# IWRL6432 register map
File version: 1.0
CPU: CM4 1.0, other endian, MPU, FPU, 3 interrupt priority bits
Registers are 32-bit, read-write, reset 0x0 unless marked. A register's access mark holds for its fields unless they carry their own. Offsets are from the block's base; [hi:lo] are bit positions; {n}, {i} and the like mark numbered series; 'fields as' and 'values as' point back to an identical list.

## APP_RCM
Base 0x56040000
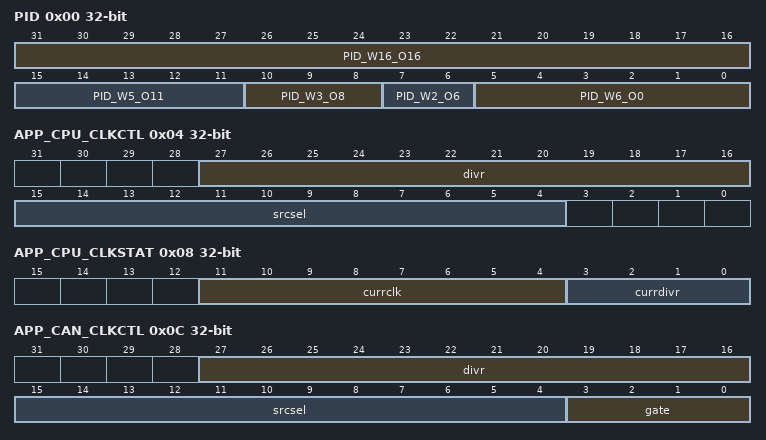
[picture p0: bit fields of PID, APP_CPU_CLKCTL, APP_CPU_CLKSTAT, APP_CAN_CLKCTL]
0x00 PID
  [31:16] PID_W16_O16, [15:11] PID_W5_O11, [10:8] PID_W3_O8, [7:6] PID_W2_O6, [5:0] PID_W6_O0
0x04 APP_CPU_CLKCTL
  [27:16] divr — [27:16] Divide value 0x0 : div1 0x1 : div2 0x2 : div3 . . 0xF = div16 Data should be loaded as multibit. For example: if divider value of '0x8' should be selected then '0x888' should be configured to the register.
  [15:4] srcsel — [15:4] Select the source clock: 0x0 : OSC_CLK 0x1 : SLOW_CLK 0x2 : MDLL_CLK 0x3 : FAST_CLK 0x4 : SLOW_CLK 0x5 : SLOW_CLK 0x6 : SLOW_CLK 0x7 : SLOW_CLK For other values if the lower 3 bits matches with above, corresponding clock is selected. Data should be loaded as multibit. For example: if Clock source 0x5 should be selected then 0x555 should be configured to the register.
0x08 APP_CPU_CLKSTAT
  [11:4] currclk — [11:4] Current Clock selected by GCM Clock Mux 0x1 : XTALCLK 0x2 : XTALCLKX2 0x4 : MDLL 0x8 : APLL/DPLL 0x10 : RCCLK
  [3:0] currdivr — [3:0] Gives the current divr setting used by the clock divider.
0x0C APP_CAN_CLKCTL
  [27:16] divr — [27:16] Divide value 0x0 : div1 0x1 : div2 0x2 : div3 . . 0xF = div16 Data should be loaded as multibit. For example: if divider value of '0x8' should be selected then '0x888' should be configured to the register.
  [15:4] srcsel — [15:4] 0x0 : OSC_CLK 0x1 : OSC_CLKX2 0x2 : MDLL_CLK 0x3 : FAST_CLK 0x4 : SLOW_CLK 0x5 : SLOW_CLK 0x6 : SLOW_CLK 0x7 : SLOW_CLKFor other values if the lower 3 bits matches with above, corresponding clock is selected. Data should be loaded as multibit. For example: if Clock source 0x5 should be selected then 0x555 should be configured to the register.
  [3:0] gate — [3:0] 0x0 : Enable the Clock 0x7 : Gate the clock
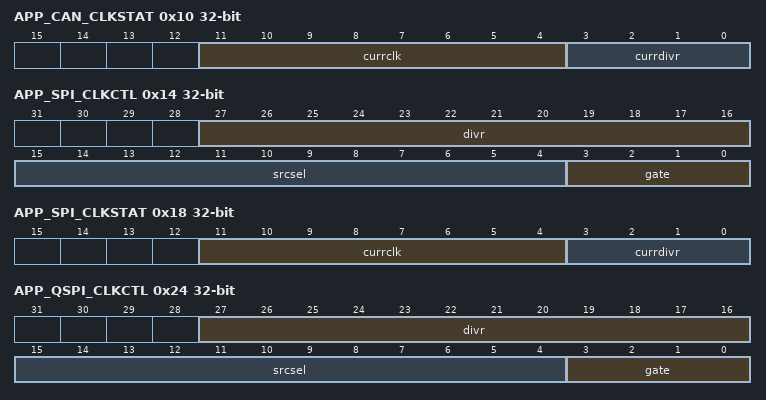
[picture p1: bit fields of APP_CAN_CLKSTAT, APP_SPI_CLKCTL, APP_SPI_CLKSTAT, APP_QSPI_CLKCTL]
0x10 APP_CAN_CLKSTAT
  fields as APP_CPU_CLKSTAT
0x14 APP_SPI_CLKCTL
  [27:16] divr — [27:16] Divide value 0x0 : div1 0x1 : div2 0x2 : div3 . . 0xF = div16 Data should be loaded as multibit. For example: if divider value of '0x8' should be selected then '0x888' should be configured to the register.
  [15:4] srcsel — [15:4] 0x0 : OSC_CLK 0x1 : OSC_CLKX2 0x2 : MDLL_CLK 0x3 : FAST_CLK 0x4 : SLOW_CLK 0x5 : SLOW_CLK 0x6 : SLOW_CLK 0x7 : SLOW_CLK For other values if the lower 3 bits matches with above, corresponding clock is selected. Data should be loaded as multibit. For example: if Clock source 0x5 should be selected then 0x555 should be configured to the register.
  [3:0] gate — [3:0] 0x0 : Enable the Clock 0x7 : Gate the clock
0x18 APP_SPI_CLKSTAT
  fields as APP_CPU_CLKSTAT
0x1C APP_SPI_BUSIF_CLKCTL
  [11:0] divr — [11:0] Divide value 0x0 : div1 0x1 : div2 0x2 : div3 . . 0xF = div16 Data should be loaded as multibit. For example: if divider value of '0x8' should be selected then '0x888' should be configured to the register.
0x20 APP_SPI_BUSIF_CLKSTAT
  [3:0] currdivr — [3:0] Gives the current divr setting used by the clock divider.
0x24 APP_QSPI_CLKCTL
  fields as APP_SPI_CLKCTL
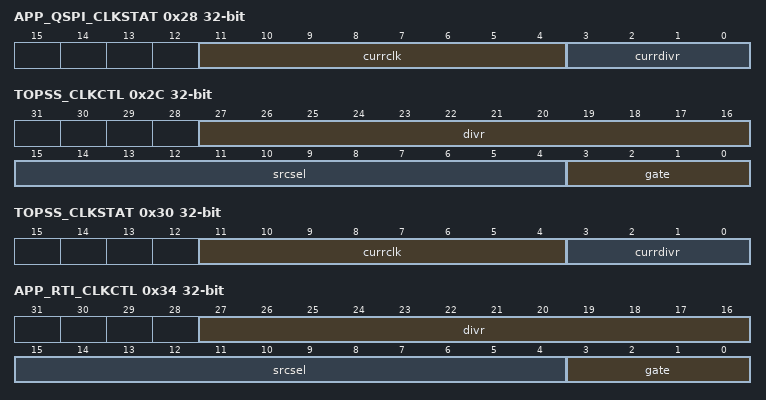
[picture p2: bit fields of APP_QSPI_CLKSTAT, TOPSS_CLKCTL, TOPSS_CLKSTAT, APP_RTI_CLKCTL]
0x28 APP_QSPI_CLKSTAT
  fields as APP_CPU_CLKSTAT
0x2C TOPSS_CLKCTL
  [27:16] divr — [27:16] Divide value 0x0 : div1 0x1 : div2 0x2 : div3 . . 0xF = div16 Data should be loaded as multibit. For example: if divider value of '0x8' should be selected then '0x888' should be configured to the register.
  [15:4] srcsel — [15:4] 0x0 : OSC_CLK 0x1 : SLOW_CLK 0x2 : MDLL 0x3 : FAST_CLK 0x4 : SLOW_CLK For other values if the lower 3 bits matches with above, corresponding clock is selected. Data should be loaded as multibit. For example: if Clock source 0x5 should be selected then 0x555 should be configured to the register.
  [3:0] gate — [3:0] 0x0 : Enable the Clock 0x7 : Gate the clock
0x30 TOPSS_CLKSTAT
  fields as APP_CPU_CLKSTAT
0x34 APP_RTI_CLKCTL
  [27:16] divr — [27:16] Divide value 0x0 : div1 0x1 : div2 0x2 : div3 . . 0xF = div16 Data should be loaded as multibit. For example: if divider value of '0x8' should be selected then '0x888' should be configured to the register.
  [15:4] srcsel — [15:4] 0x0 : OSC_CLK 0x1 : XREF_IN 0x2 : OSC_CLK (Ungated OSC_CLK for RTI in Sleep mode) 0x3 : SLOW_CLK 0x4 : SLOW_CLK 0x5 : SLOW_CLK 0x6 : SLOW_CLK 0x7 : SLOW_CLK For other values if the lower 3 bits matches with above, corresponding clock is selected. Data should be loaded as multibit. For example: if Clock source 0x5 should be selected then 0x555 should be configured to the register.
  [3:0] gate — [3:0] 0x0 : Enable the Clock 0x7 : Gate the clock
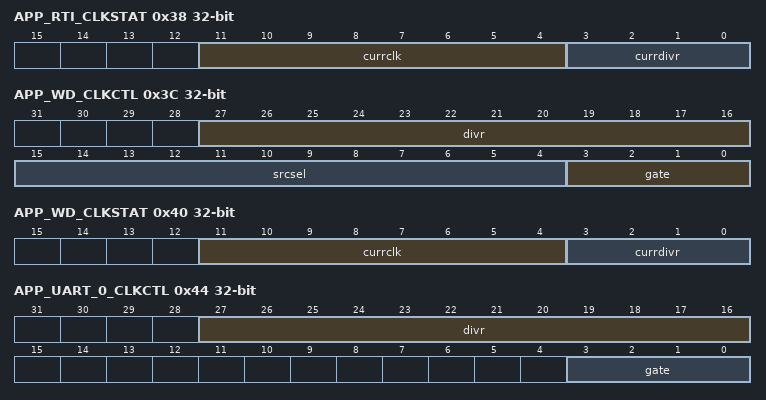
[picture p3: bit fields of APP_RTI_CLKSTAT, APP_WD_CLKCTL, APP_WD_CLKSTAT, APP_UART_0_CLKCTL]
0x38 APP_RTI_CLKSTAT
  fields as APP_CPU_CLKSTAT
0x3C APP_WD_CLKCTL
  [27:16] divr — [27:16] Divide value 0x0 : div1 0x1 : div2 0x2 : div3 . . 0xF = div16 Data should be loaded as multibit. For example: if divider value of '0x8' should be selected then '0x888' should be configured to the register.
  [15:4] srcsel — [15:4] 0x0 : OSC_CLK 0x1 : XREF_IN 0x2 : OSC_CLK 0x3 : SLOW_CLK 0x4 : SLOW_CLK 0x5 : SLOW_CLK 0x6 : SLOW_CLK 0x7 : SLOW_CLK For other values if the lower 3 bits matches with above, corresponding clock is selected. Data should be loaded as multibit. For example: if Clock source 0x5 should be selected then 0x555 should be configured to the register.
  [3:0] gate — [3:0] 0x0 : Enable the Clock 0x7 : Gate the clock
0x40 APP_WD_CLKSTAT
  fields as APP_CPU_CLKSTAT
0x44 APP_UART_0_CLKCTL
  [27:16] divr — [27:16] Divide value 0x0 : div1 0x1 : div2 0x2 : div3 . . 0xF = div16 Data should be loaded as multibit. For example: if divider value of '0x8' should be selected then '0x888' should be configured to the register.
  [3:0] gate — [3:0] 0x0 : Enable the Clock 0x7 : Gate the clock
0x48 APP_UART_0_CLKSTAT
  fields as APP_SPI_BUSIF_CLKSTAT
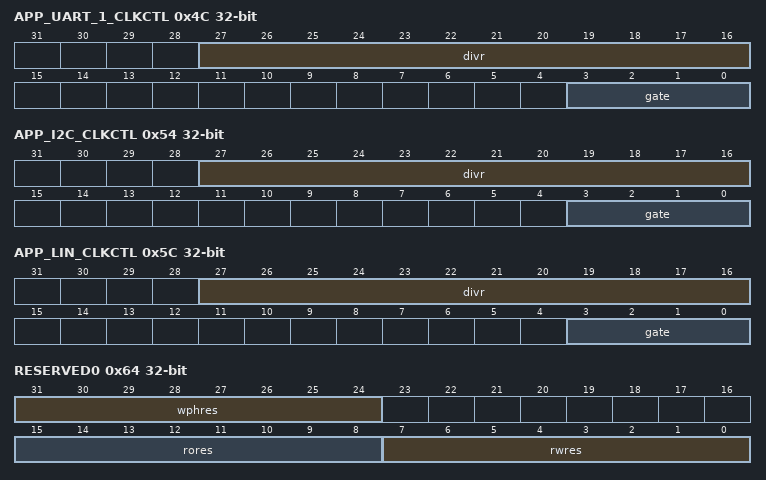
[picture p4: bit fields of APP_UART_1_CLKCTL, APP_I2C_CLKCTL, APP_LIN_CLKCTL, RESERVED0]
0x4C APP_UART_1_CLKCTL
  fields as APP_UART_0_CLKCTL
0x50 APP_UART_1_CLKSTAT
  fields as APP_SPI_BUSIF_CLKSTAT
0x54 APP_I2C_CLKCTL
  fields as APP_UART_0_CLKCTL
0x58 APP_I2C_CLKSTAT
  fields as APP_SPI_BUSIF_CLKSTAT
0x5C APP_LIN_CLKCTL
  fields as APP_UART_0_CLKCTL
0x60 APP_LIN_CLKSTAT
  fields as APP_SPI_BUSIF_CLKSTAT
0x64 RESERVED0
  [31:24] wphres — [31:24] Reserved
  [15:8] rores — [15:8] Reserved
  [7:0] rwres — [7:0] Bit 2:0 - Software reset for hwass cba3to2 and m64top32 bridge instances in appss. (reset value - 0) Bit 5:3 - Software reset for fecss p2p async bridge instance in appss. (reset value - 0) 0x0 : Release the reset 0x7 : Assert the reset Bit 31:6 - Reserved
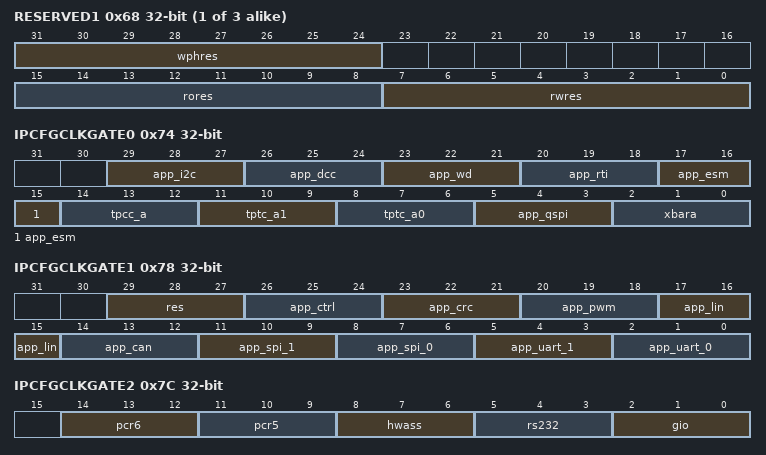
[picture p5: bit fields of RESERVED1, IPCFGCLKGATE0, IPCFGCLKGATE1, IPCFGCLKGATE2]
{0x64+4i} RESERVED{i} (i=1..3)
  [31:24] wphres — [31:24] Reserved
  [15:8] rores — [15:8] Reserved
  [7:0] rwres — [7:0] Reserved
0x74 IPCFGCLKGATE0
  [29:27] app_i2c — [29:27] 0x0 : Enable the Clock 0x7 : Gate the clock
  [26:24] app_dcc — [26:24] 0x0 : Enable the Clock 0x7 : Gate the clock
  [23:21] app_wd — [23:21] 0x0 : Enable the Clock 0x7 : Gate the clock
  [20:18] app_rti — [20:18] 0x0 : Enable the Clock 0x7 : Gate the clock
  [17:15] app_esm — [17:15] 0x0 : Enable the Clock 0x7 : Gate the clock
  [14:12] tpcc_a — [14:12] 0x0 : Enable the Clock 0x7 : Gate the clock
  [11:9] tptc_a1 — [11:9] 0x0 : Enable the Clock 0x7 : Gate the clock
  [8:6] tptc_a0 — [8:6] 0x0 : Enable the Clock 0x7 : Gate the clock
  [5:3] app_qspi — [5:3] 0x0 : Enable the Clock 0x7 : Gate the clock
  [2:0] xbara — [2:0] Reserved Setting this bit does not cause any affect to any logic
0x78 IPCFGCLKGATE1
  [29:27] res — [29:27] 0x0 : Enable the Clock 0x7 : Gate the clock
  [26:24] app_ctrl — [26:24] 0x0 : Enable the Clock 0x7 : Gate the clock
  [23:21] app_crc — [23:21] 0x0 : Enable the Clock 0x7 : Gate the clock
  [20:18] app_pwm — [20:18] 0x0 : Enable the Clock 0x7 : Gate the clock
  [17:15] app_lin — [17:15] 0x0 : Enable the Clock 0x7 : Gate the clock
  [14:12] app_can — [14:12] 0x0 : Enable the Clock 0x7 : Gate the clock
  [11:9] app_spi_1 — [11:9] 0x0 : Enable the Clock 0x7 : Gate the clock
  [8:6] app_spi_0 — [8:6] 0x0 : Enable the Clock 0x7 : Gate the clock
  [5:3] app_uart_1 — [5:3] 0x0 : Enable the Clock 0x7 : Gate the clock
  [2:0] app_uart_0 — [2:0] 0x0 : Enable the Clock 0x7 : Gate the clock
0x7C IPCFGCLKGATE2
  [14:12] pcr6 — [14:12] 0x0 : Enable the Clock 0x7 : Gate the clock
  [11:9] pcr5 — [11:9] 0x0 : Enable the Clock 0x7 : Gate the clock
  [8:6] hwass — [8:6] 0x0 : Enable the Clock 0x7 : Gate the clock
  [5:3] rs232 — [5:3] 0x0 : Enable the Clock 0x7 : Gate the clock
  [2:0] gio — [2:0] 0x0 : Enable the Clock 0x7 : Gate the clock
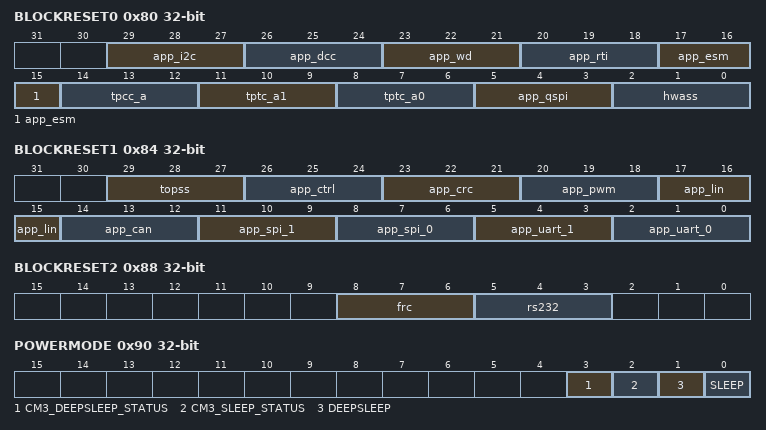
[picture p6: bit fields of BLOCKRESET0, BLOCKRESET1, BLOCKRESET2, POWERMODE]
0x80 BLOCKRESET0
  [29:27] app_i2c — [29:27] 0x0 : Release the reset 0x7 : Assert the reset
  [26:24] app_dcc — [26:24] 0x0 : Release the reset 0x7 : Assert the reset
  [23:21] app_wd — [23:21] 0x0 : Release the reset 0x7 : Assert the reset
  [20:18] app_rti — [20:18] 0x0 : Release the reset 0x7 : Assert the reset
  [17:15] app_esm — [17:15] 0x0 : Release the reset 0x7 : Assert the reset
  [14:12] tpcc_a — [14:12] 0x0 : Release the reset 0x7 : Assert the reset
  [11:9] tptc_a1 — [11:9] 0x0 : Release the reset 0x7 : Assert the reset
  [8:6] tptc_a0 — [8:6] 0x0 : Release the reset 0x7 : Assert the reset
  [5:3] app_qspi — [5:3] 0x0 : Release the reset 0x7 : Assert the reset
  [2:0] hwass — [2:0] 0x0 : Release the reset 0x7 : Assert the reset
0x84 BLOCKRESET1
  [29:27] topss — [29:27] 0x0 : Release the reset 0x7 : Assert the reset
  [26:24] app_ctrl — [26:24] 0x0 : Release the reset 0x7 : Assert the reset
  [23:21] app_crc — [23:21] 0x0 : Release the reset 0x7 : Assert the reset
  [20:18] app_pwm — [20:18] 0x0 : Release the reset 0x7 : Assert the reset
  [17:15] app_lin — [17:15] 0x0 : Release the reset 0x7 : Assert the reset
  [14:12] app_can — [14:12] 0x0 : Release the reset 0x7 : Assert the reset
  [11:9] app_spi_1 — [11:9] 0x0 : Release the reset 0x7 : Assert the reset
  [8:6] app_spi_0 — [8:6] 0x0 : Release the reset 0x7 : Assert the reset
  [5:3] app_uart_1 — [5:3] 0x0 : Release the reset 0x7 : Assert the reset
  [2:0] app_uart_0 — [2:0] 0x0 : Release the reset 0x7 : Assert the reset
0x88 BLOCKRESET2
  [8:6] frc — [8:6] 0x0 : Release the reset 0x7 : Assert the reset
  [5:3] rs232 — [5:3] 0x0 : Release the reset 0x7 : Assert the reset
0x8C PLATFORM_SIGNATURE
  [31:0] signature — [31:0] Platform signature to identify the platform
0x90 POWERMODE
  [3] CM3_DEEPSLEEP_STATUS — [3:3] CM3 Core Deep Sleep Status
  [2] CM3_SLEEP_STATUS — [2:2] CM3 Core Sleep Status
  [1] DEEPSLEEP — [1:1] 0x0 : CM4 CORE DEEP SLEEP 0x1 : DEVICE DEEP SLEEP
  [0] SLEEP — [0:0] 0x0 : CM4 CORE SLEEP 0x1 : DEVICE SLEEP
0x94 RST_WFICHECK
  [2:0] cpu — [2:0] Writing '000' will disable check for WFI before local reset assertion of app cpu
0x98 RST_ASSERTDLY
  [7:0] common — [7:0] Value decides number of cycles reset should be asserted for cpu
0x9C RST2ASSERTDLY
  [15:8] cpu — [15:8] Value decides number of cycles to be held before asserting reset for app cpu
0xA0 RST_FSM_TRIG
  [2:0] cpu — [2:0] FSM Reset Trigger
0xA4 RST_CAUSE
  [7:0] common — [7:0] Reset cause register for APP CPU 0x00 - All cleared 0x01 - Power On Reset (PoR) 0x02 - Subsystem Reset (Combination of Warm Reset initiated from PRCM using LPRADAR:TOP_PRCM:RST_APP_PD_SOFT_RESET and PoR reset) 0x04 - STC RESET 0x08 - Reserved 0x10 - CPU Only Reset triggered by writing to LPRADAR:APP_RCM:RST_FSM_TRIG<RST_FSM_TRIG_CPU> (self triggered CPU reset during MEMSWAP/ECLIPSE mode to wait for WFI to assert the reset to CPU) 0x20 - Core Reset initiated from PRCM using LPRADAR:TOP_PRCM:RST_SOFT_APP_CORE_SYSRESET_REQ (reset CPU unconditionally - by debugger) or LPRADAR:TOP_PRCM:APP_CORE_SYSRESET_PARAM_WAKEUP_OUT_STATE 0x40 - Reserved
0xA8 RST_CAUSE_CLR
  [2:0] cpu — [2:0] Writing '111' will clear the RST_CAUSE register
0xAC XTALCLK_CLK_GATE
  [2:0] XTALCLK_CLK_GATE — [2:0] RESERVED
0xB0 XTALCLKX2_CLK_GATE
  [2:0] XTALCLKX2_CLK_GATE — [2:0] Writing 3'b111 will gate the XTALX2 clock.Writing 3'b000 will ungate the clock.
0xB4 APLLDIV2_CLK_GATE
  [2:0] APLLDIV2_CLK_GATE — [2:0] Writing 3'b111 will gate the APLL/2clock to EDCC.Writing 3'b000 will ungate the clock.
0xB8 DFT_APPSS_LSTC_CLK_GATE
  [2:0] DFT_APPSS_LSTC_CLK_GATE — [2:0] Writing 3'b111 will gate the clock to LSTC.Writing 3'b000 will ungate the clock.
0xBC DFT_APPSS_LSTC_VBUSP_CLK_GATE
  [2:0] enable — [2:0] 3'b000 : Gate clock to LSTC VBUSP 3'b111 : Ungate Clock to LSTC VBUSP
0xC0 APP_ROM_CLOCK_GATE
  [2:0] enable — [2:0] 3'b000 : Ungate clock to APP ROM 3'b111 : Gate Clock to APP ROM
0xC4 APP_RAM1_CLOCK_GATE
  [2:0] enable — [2:0] 3'b000 : Ungate clock to APP RAM1 3'b111 : Gate Clock to APP_RAM1
0xC8 APP_RAM2_CLOCK_GATE
  [2:0] enable — [2:0] 3'b000 : Ungate clock to APP RAM2 3'b111 : Gate Clock to APP RAM2
0xCC APP_RAM3_CLOCK_GATE
  [2:0] enable — [2:0] 3'b000 : Ungate clock to APP RAM3 3'b111 : Gate Clock to APP RAM3
0xD0 CFG_XBARA_DYNAMIC_CG
  [2:0] enable — [2:0] Enable APPSS crossbar dynamic clock gating. 1 - Dynamic clock gating feature is enabled. When the feature is enabed, the CM4 should monitor for any possible pending transactions from various masters like DMA/NWA and if no transaction is expected to be iniated by the masters, the CM4 executes WFI. On ssertion of WFI signal, the clock to crossbar is gated. The clock is automatically ungated under two conditions (i) when the WFI signal is deasserted by any interrupted (ii) when any of the APPSS TPCC triggers are asserted. Instead of WFI, cfg_xbara_set_dynamic_cg also can be used to start the clock gating. 0 - Dynamic clock gating feature is disabled. The clock to APPSS crossbar is not gated dynamically. The clock to APPSS crossbar is gated/ungated as per device ice level power states.
0xD4 CFG_TPTC1_DYNAMIC_CG
  [2:0] enable — [2:0] Enable APPSS TPTC1 crossbar dynamic clock gating. 1 - Dynamic clock gating feature is enabled. Same behaviour as cfg_xbara_dynamic_cg_en - for both entry to clock gating and exit from clock gating. WFI or cfg_tptc1_set_dynamic_cg 0 - Dynamic clock gating feature is disabled. The clock to APPSS TPTC1 crossbar is not gated dynamically. The clock to APPSS TPTC1 crossbar is gated/ungated as per device ice level power states.
0xD8 CFG_TPTC2_DYNAMIC_CG
  [2:0] enable — [2:0] Enable APPSS TPTC2 crossbar dynamic clock gating. 1 - Dynamic clock gating feature is enabled. Same behaviour as cfg_xbara_dynamic_cg_en - for both entry to clock gating and exit from clock gating. WFI or cfg_tptc2_set_dynamic_cg 0 - Dynamic clock gating feature is disabled. The clock to APPSS TPTC2 crossbar is not gated dynamically. The clock to APPSS TPTC2 crossbar is gated/ungated as per device ice level power states
0xDC CFG_XBARA_SET_DYNAMIC_CG
  [0] set — [0:0] Start APPSS crossbar dynamic clock gating. This is used instead of WFI. 1 - Start the clock gating. In order to start again, write 0 followed by 1. Rise edge is detected internally, to start the clock gating. 0 - Clock is ungated. Fall edge is detected internally to ungate the clock.
0xE0 CFG_TPTC1_SET_DYNAMIC_CG
  [0] set — [0:0] Start APPSS tptc1 dynamic clock gating. This is used instead of WFI. 1 - Start the clock gating. In order to start again, write 0 followed by 1. Rise edge is detected internally, to start the clock gating. 0 - Clock is ungated. Fall edge is detected internally to ungate the clock.
0xE4 CFG_TPTC2_SET_DYNAMIC_CG
  [0] set — [0:0] Start APPSS tptc2 dynamic clock gating. This is used instead of WFI. 1 - Start the clock gating. In order to start again, write 0 followed by 1. Rise edge is detected internally, to start the clock gating. 0 - Clock is ungated. Fall edge is detected internally to ungate the clock.
0xE8 CM4_FORCE_HCLK_GATE
  [2:0] enable — [2:0] 3'b000 - CM4 HCLK is ungated 3'b111 - CM4 HCLK is gated
0xEC LIN_SCI_DIV
  [7:0] val — [7:0] ICG Based Divider for LIN
0xF0 APP_LSTC_EN
  [0] enable — [0:0] Enable vbusp_req and clk_en for app lstc
0x1008 LOCK0_KICK0 — - KICK0 component
  [31:0] KICK0_COMPONENT — [31:0] - KICK0 component
0x100C LOCK0_KICK1 — - KICK1 component
  [31:0] KICK1_COMPONENT — [31:0] - KICK1 component
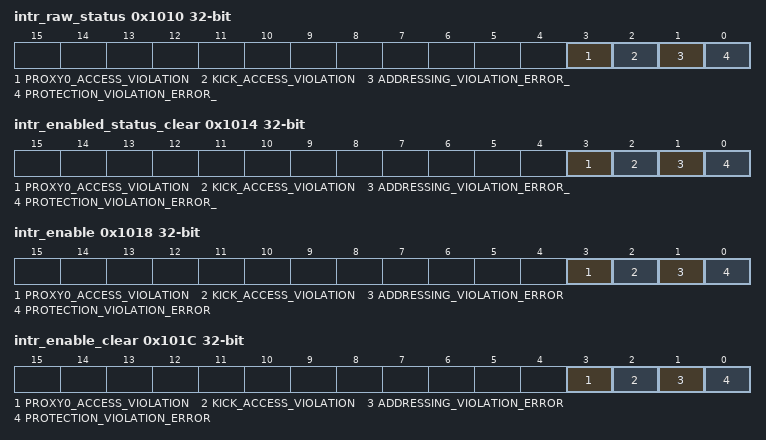
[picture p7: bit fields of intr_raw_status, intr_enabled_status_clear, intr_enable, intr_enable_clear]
0x1010 intr_raw_status — Interrupt Raw Status/Set Register
  [3] PROXY0_ACCESS_VIOLATION — [3:3] Proxy0 access violation error. Raw status is read. Write a 1 to set the status. Writing a 0 has no effect.
  [2] KICK_ACCESS_VIOLATION — [2:2] Kick access violation error. Raw status is read. Write a 1 to set the status. Writing a 0 has no effect.
  [1] ADDRESSING_VIOLATION_ERROR_ — [1:1] Addressing violation error. Raw status is read. Write a 1 to set the status. Writing a 0 has no effect.
  [0] PROTECTION_VIOLATION_ERROR_ — [0:0] Protection violation error. Raw status is read. Write a 1 to set the status. Writing a 0 has no effect.
0x1014 intr_enabled_status_clear — Interrupt Enabled Status/Clear register
  [3] PROXY0_ACCESS_VIOLATION — [3:3] Proxy0 access violation error. Enabled status is read. Write a 1 to clear the status. Writing a 0 has no effect.
  [2] KICK_ACCESS_VIOLATION — [2:2] Kick access violation error. Enabled status is read. Write a 1 to clear the status. Writing a 0 has no effect.
  [1] ADDRESSING_VIOLATION_ERROR_ — [1:1] Addressing violation error. Enabled status is read. Write a 1 to clear the status. Writing a 0 has no effect.
  [0] PROTECTION_VIOLATION_ERROR_ — [0:0] Protection violation error. Enabled status is read. Write a 1 to clear the status. Writing a 0 has no effect.
0x1018 intr_enable — Interrupt Enable register
  [3] PROXY0_ACCESS_VIOLATION — [3:3] Proxy0 access violation error enable. Write a 1 to set the enable. Writing a 0 has no effect.
  [2] KICK_ACCESS_VIOLATION — [2:2] Kick access violation error enable. Write a 1 to set the enable. Writing a 0 has no effect.
  [1] ADDRESSING_VIOLATION_ERROR — [1:1] Addressing violation error enable. Write a 1 to set the enable. Writing a 0 has no effect.
  [0] PROTECTION_VIOLATION_ERROR — [0:0] Protection violation error enable. Write a 1 to set the enable. Writing a 0 has no effect.
0x101C intr_enable_clear — Interrupt Enable Clear register
  [3] PROXY0_ACCESS_VIOLATION — [3:3] Proxy0 access violation error enable clear. Write a 1 to clear the enable. Writing a 0 has no effect.
  [2] KICK_ACCESS_VIOLATION — [2:2] Kick access violation error enable clear. Write a 1 to clear the enable. Writing a 0 has no effect.
  [1] ADDRESSING_VIOLATION_ERROR — [1:1] Addressing violation error enable clear. Write a 1 to clear the enable. Writing a 0 has no effect.
  [0] PROTECTION_VIOLATION_ERROR — [0:0] Protection violation error enable clear. Write a 1 to clear the enable. Writing a 0 has no effect.
0x1020 eoi
  [7:0] EOI_VECTOR_VALUE_ — [7:0] EOI vector value. Write this with interrupt distribution value in the chip.
0x1024 fault_address
  [31:0] FAULT_ADDRESS_ — [31:0] Fault Address.
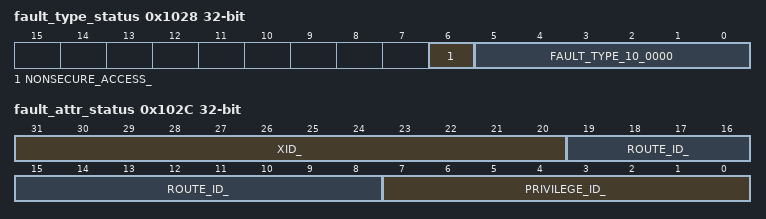
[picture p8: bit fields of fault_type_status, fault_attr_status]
0x1028 fault_type_status
  [6] NONSECURE_ACCESS_ — [6:6] Non-secure access.
  [5:0] FAULT_TYPE_10_0000 — [5:0] Fault Type 10_0000 = Supervisor read fault - priv = 1 dir = 1 dtype != 1 01_0000 = Supervisor write fault - priv = 1 dir = 0 00_1000 = Supervisor execute fault - priv = 1 dir = 1 dtype = 1 00_0100 = User read fault - priv = 0 dir = 1 dtype = 1 00_0010 = User write fault - priv = 0 dir = 0 00_0001 = User execute fault - priv = 0 dir = 1 dtype = 1 00_0000 = No fault
0x102C fault_attr_status — Fault Attribute Status register
  [31:20] XID_ — [31:20] XID.
  [19:8] ROUTE_ID_ — [19:8] Route ID.
  [7:0] PRIVILEGE_ID_ — [7:0] Privilege ID.
0x1030 fault_clear
  [0] FAULT_CLEAR__WRITING — [0:0] Fault clear. Writing a 1 clears the current fault. Writing a 0 has no effect.

## PLLDIG_CTRL
Base 0x5B040000
Registers as APP_RCM, without APP_CPU_CLKCTL, APP_CPU_CLKSTAT, APP_CAN_CLKCTL, APP_CAN_CLKSTAT, APP_SPI_CLKCTL, APP_SPI_CLKSTAT, APP_SPI_BUSIF_CLKCTL, APP_SPI_BUSIF_CLKSTAT, APP_QSPI_CLKCTL, APP_QSPI_CLKSTAT, TOPSS_CLKCTL, TOPSS_CLKSTAT, APP_RTI_CLKCTL, APP_RTI_CLKSTAT, APP_WD_CLKCTL, APP_WD_CLKSTAT, APP_UART_0_CLKCTL, APP_UART_0_CLKSTAT, APP_UART_1_CLKCTL, APP_UART_1_CLKSTAT, APP_I2C_CLKCTL, APP_I2C_CLKSTAT, APP_LIN_CLKCTL, APP_LIN_CLKSTAT, RESERVED{n} (n=0..3), IPCFGCLKGATE{n} (n=0..2), BLOCKRESET{n} (n=0..2), PLATFORM_SIGNATURE, POWERMODE, RST_WFICHECK, RST_ASSERTDLY, RST2ASSERTDLY, RST_FSM_TRIG, RST_CAUSE, RST_CAUSE_CLR, XTALCLK_CLK_GATE, XTALCLKX2_CLK_GATE, APLLDIV2_CLK_GATE, DFT_APPSS_LSTC_CLK_GATE, DFT_APPSS_LSTC_VBUSP_CLK_GATE, APP_ROM_CLOCK_GATE, APP_RAM{n}_CLOCK_GATE (n=1..3), CFG_XBARA_DYNAMIC_CG, CFG_TPTC1_DYNAMIC_CG, CFG_TPTC2_DYNAMIC_CG, CFG_XBARA_SET_DYNAMIC_CG, CFG_TPTC1_SET_DYNAMIC_CG, CFG_TPTC2_SET_DYNAMIC_CG, CM4_FORCE_HCLK_GATE, LIN_SCI_DIV, APP_LSTC_EN; these are added or differ:
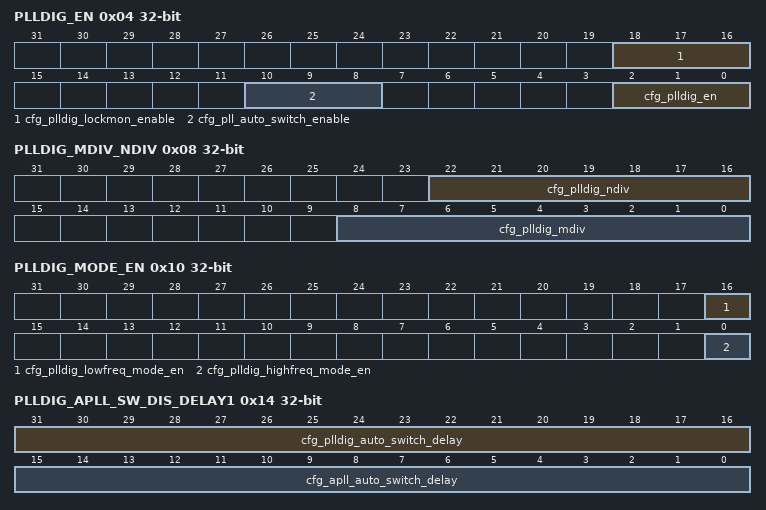
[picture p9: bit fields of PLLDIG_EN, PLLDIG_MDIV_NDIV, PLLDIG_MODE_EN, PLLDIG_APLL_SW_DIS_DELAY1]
0x04 PLLDIG_EN
  [18:16] cfg_plldig_lockmon_enable — [18:16] PLL DIG lockmon enable 0x0 = PLL DIG lockmon disbale 0x7 = PLL DIG lockmon enable
  [10:8] cfg_pll_auto_switch_enable — [10:8] PLL DIG and APLL auto switch enable 0x0 = PLL DIG wont be auto turn off when APLL is enable 0x7 = PLL DIG will be auto turn off when APLL is enable
  [2:0] cfg_plldig_en — [2:0] PLL DIG enable 0x0 = PLL DIG disable 0x7 = PLL DIG enable
0x08 PLLDIG_MDIV_NDIV
  [22:16] cfg_plldig_ndiv — [22:16] NDIV value for the PLL DIG Input clock divider settings .NDIV value directly programs the 7-bit pre- divider. Divide value ranges from 2 to 127. NDIV value has to be chosen based on the REF_CLKIN frequency so as to get the internal reference frequency of the PLL closest to 2Mhz
  [8:0] cfg_plldig_mdiv — [8:0] MDIV value for the PLL DIG Feedback divider settings. MDIV value directly programs the 9-bit feedback divider. Divide value ranges from 2 to 511. MDIV value has to be chosen to generate the required clock out frequency from the 2Mhz internal PLL reference
0x0C PLLDIG_CTRL
  [31:0] cfg_plldig_ctrl — [31:0] PLL DIG test controls
0x10 PLLDIG_MODE_EN
  [16] cfg_plldig_lowfreq_mode_en — [16:16] PLL DIG high frequency mode operation, Divide by 2 the PLL clock out
  [0] cfg_plldig_highfreq_mode_en — [0:0] PLL DIG high frequency mode operation
0x14 PLLDIG_APLL_SW_DIS_DELAY1
  [31:16] cfg_plldig_auto_switch_delay — [31:16] Delay to switch the PLL clock source when the auto PLL switch mode is enable
  [15:0] cfg_apll_auto_switch_delay — [15:0] Delay to switch the PLL clock source when the auto PLL switch mode is enable
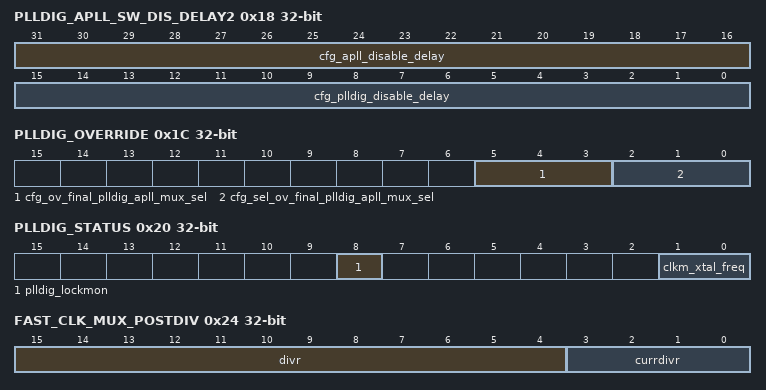
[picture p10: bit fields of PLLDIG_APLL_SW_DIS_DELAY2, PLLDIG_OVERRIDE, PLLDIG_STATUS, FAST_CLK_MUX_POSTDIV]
0x18 PLLDIG_APLL_SW_DIS_DELAY2
  [31:16] cfg_apll_disable_delay — [31:16] Delay between the PLL clock source switching and disabling of the APLL
  [15:0] cfg_plldig_disable_delay — [15:0] Delay between the PLL clock source switching and disabling of the PLL DIG
0x1C PLLDIG_OVERRIDE
  [5:3] cfg_ov_final_plldig_apll_mux_sel — [5:3] Override control for the fast clock src mux select 0x0 = PLL DIG selected as fast clock 0x7 = APLL selected as fast clock
  [2:0] cfg_sel_ov_final_plldig_apll_mux_sel — [2:0] Mux select control to select the override value of the fast clock src mux select 0x0 = functional value selected for the fast clock src mux select 0x7 = Override value selected for the fast clock src mux select
0x20 PLLDIG_STATUS
  [8] plldig_lockmon — [8:8] PLL DIG lockmon status
  [1:0] clkm_xtal_freq — [1:0] XTAL clock frequency status, 0x0 = 25MHz 0x1 = 40MHz 0x2 = 26MHz 0x3 = 38.4MHz
0x24 FAST_CLK_MUX_POSTDIV
  [15:4] divr — [15:4] Divider value for FAST selected clock. Data should be loaded as multibit. For example: if divider value of 8 (1000) needs to be selected then '100010001000' should be configured to the register.
  [3:0] currdivr — [3:0] Status shows the current divider value choosen for FAST_CLK.
0x28 FAST_CLK_STATUS
  [1:0] currclk — [1:0] Current Clock selected by GCM Clock Mux 0x1 : PLLDIG 0x2 : APLL
